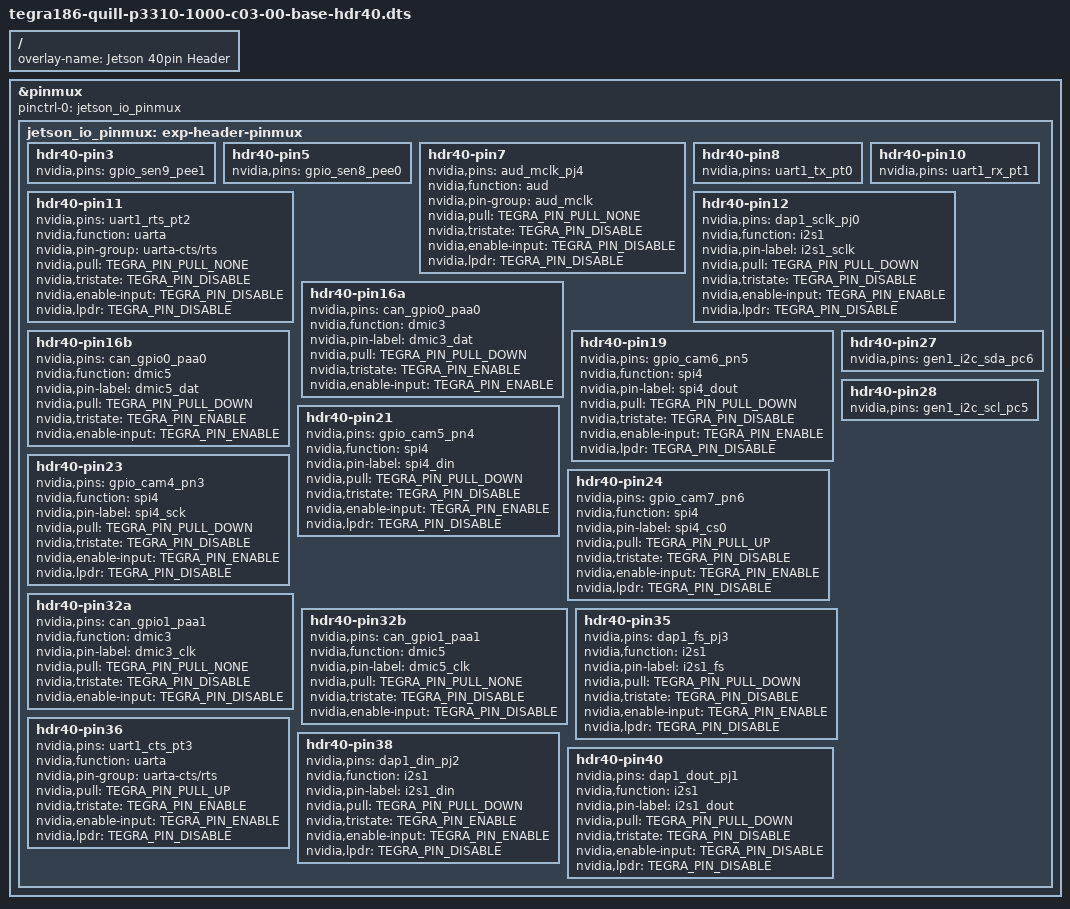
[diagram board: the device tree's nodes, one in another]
// SPDX-License-Identifier: GPL-2.0-only
/*
 * Device-tree overlay for tegra186-quill-p3310-1000-c03-00-base
 * 40-pin Expansion Header.
 *
 * Copyright (c) 2019-2021 NVIDIA CORPORATION. All rights reserved.
 *
 */

/dts-v1/;
/plugin/;

#include <dt-bindings/pinctrl/pinctrl-tegra.h>
#include <dt-common/jetson/tegra186-quill-p3310-1000-c03-00-base.h>

/ {
	overlay-name = "Jetson 40pin Header";
	compatible = JETSON_COMPATIBLE;

	fragment@0 {
		target = <&pinmux>;
		__overlay__ {
			pinctrl-names = "default";
			pinctrl-0 = <&jetson_io_pinmux>;
			jetson_io_pinmux: exp-header-pinmux {
				hdr40-pin3 {
					nvidia,pins = "gpio_sen9_pee1";
				};
				hdr40-pin5 {
					nvidia,pins = "gpio_sen8_pee0";
				};
				hdr40-pin7 {
					nvidia,pins = "aud_mclk_pj4";
					nvidia,function = "aud";
					nvidia,pin-group = "aud_mclk";
					nvidia,pull = <TEGRA_PIN_PULL_NONE>;
					nvidia,tristate = <TEGRA_PIN_DISABLE>;
					nvidia,enable-input = <TEGRA_PIN_DISABLE>;
					nvidia,lpdr = <TEGRA_PIN_DISABLE>;
				};
				hdr40-pin8 {
					nvidia,pins = "uart1_tx_pt0";
				};
				hdr40-pin10 {
					nvidia,pins = "uart1_rx_pt1";
				};
				hdr40-pin11 {
					nvidia,pins = "uart1_rts_pt2";
					nvidia,function = "uarta";
					nvidia,pin-group = "uarta-cts/rts";
					nvidia,pull = <TEGRA_PIN_PULL_NONE>;
					nvidia,tristate = <TEGRA_PIN_DISABLE>;
					nvidia,enable-input = <TEGRA_PIN_DISABLE>;
					nvidia,lpdr = <TEGRA_PIN_DISABLE>;
				};
				hdr40-pin12 {
					nvidia,pins = "dap1_sclk_pj0";
					nvidia,function = "i2s1";
					nvidia,pin-label = "i2s1_sclk";
					nvidia,pull = <TEGRA_PIN_PULL_DOWN>;
					nvidia,tristate = <TEGRA_PIN_DISABLE>;
					nvidia,enable-input = <TEGRA_PIN_ENABLE>;
					nvidia,lpdr = <TEGRA_PIN_DISABLE>;
				};
				hdr40-pin16a {
					nvidia,pins = "can_gpio0_paa0";
					nvidia,function = "dmic3";
					nvidia,pin-label = "dmic3_dat";
					nvidia,pull = <TEGRA_PIN_PULL_DOWN>;
					nvidia,tristate = <TEGRA_PIN_ENABLE>;
					nvidia,enable-input = <TEGRA_PIN_ENABLE>;
				};
				hdr40-pin16b {
					nvidia,pins = "can_gpio0_paa0";
					nvidia,function = "dmic5";
					nvidia,pin-label = "dmic5_dat";
					nvidia,pull = <TEGRA_PIN_PULL_DOWN>;
					nvidia,tristate = <TEGRA_PIN_ENABLE>;
					nvidia,enable-input = <TEGRA_PIN_ENABLE>;
				};
				hdr40-pin19 {
					nvidia,pins = "gpio_cam6_pn5";
					nvidia,function = "spi4";
					nvidia,pin-label = "spi4_dout";
					nvidia,pull = <TEGRA_PIN_PULL_DOWN>;
					nvidia,tristate = <TEGRA_PIN_DISABLE>;
					nvidia,enable-input = <TEGRA_PIN_ENABLE>;
					nvidia,lpdr = <TEGRA_PIN_DISABLE>;
				};
				hdr40-pin21 {
					nvidia,pins = "gpio_cam5_pn4";
					nvidia,function = "spi4";
					nvidia,pin-label = "spi4_din";
					nvidia,pull = <TEGRA_PIN_PULL_DOWN>;
					nvidia,tristate = <TEGRA_PIN_DISABLE>;
					nvidia,enable-input = <TEGRA_PIN_ENABLE>;
					nvidia,lpdr = <TEGRA_PIN_DISABLE>;
				};
				hdr40-pin23 {
					nvidia,pins = "gpio_cam4_pn3";
					nvidia,function = "spi4";
					nvidia,pin-label = "spi4_sck";
					nvidia,pull = <TEGRA_PIN_PULL_DOWN>;
					nvidia,tristate = <TEGRA_PIN_DISABLE>;
					nvidia,enable-input = <TEGRA_PIN_ENABLE>;
					nvidia,lpdr = <TEGRA_PIN_DISABLE>;
				};
				hdr40-pin24 {
					nvidia,pins = "gpio_cam7_pn6";
					nvidia,function = "spi4";
					nvidia,pin-label = "spi4_cs0";
					nvidia,pull = <TEGRA_PIN_PULL_UP>;
					nvidia,tristate = <TEGRA_PIN_DISABLE>;
					nvidia,enable-input = <TEGRA_PIN_ENABLE>;
					nvidia,lpdr = <TEGRA_PIN_DISABLE>;
				};
				hdr40-pin27 {
					nvidia,pins = "gen1_i2c_sda_pc6";
				};
				hdr40-pin28 {
					nvidia,pins = "gen1_i2c_scl_pc5";
				};
				hdr40-pin32a {
					nvidia,pins = "can_gpio1_paa1";
					nvidia,function = "dmic3";
					nvidia,pin-label = "dmic3_clk";
					nvidia,pull = <TEGRA_PIN_PULL_NONE>;
					nvidia,tristate = <TEGRA_PIN_DISABLE>;
					nvidia,enable-input = <TEGRA_PIN_DISABLE>;
				};
				hdr40-pin32b {
					nvidia,pins = "can_gpio1_paa1";
					nvidia,function = "dmic5";
					nvidia,pin-label = "dmic5_clk";
					nvidia,pull = <TEGRA_PIN_PULL_NONE>;
					nvidia,tristate = <TEGRA_PIN_DISABLE>;
					nvidia,enable-input = <TEGRA_PIN_DISABLE>;
				};
				hdr40-pin35 {
					nvidia,pins = "dap1_fs_pj3";
					nvidia,function = "i2s1";
					nvidia,pin-label = "i2s1_fs";
					nvidia,pull = <TEGRA_PIN_PULL_DOWN>;
					nvidia,tristate = <TEGRA_PIN_DISABLE>;
					nvidia,enable-input = <TEGRA_PIN_ENABLE>;
					nvidia,lpdr = <TEGRA_PIN_DISABLE>;
				};
				hdr40-pin36 {
					nvidia,pins = "uart1_cts_pt3";
					nvidia,function = "uarta";
					nvidia,pin-group = "uarta-cts/rts";
					nvidia,pull = <TEGRA_PIN_PULL_UP>;
					nvidia,tristate = <TEGRA_PIN_ENABLE>;
					nvidia,enable-input = <TEGRA_PIN_ENABLE>;
					nvidia,lpdr = <TEGRA_PIN_DISABLE>;
				};
				hdr40-pin38 {
					nvidia,pins = "dap1_din_pj2";
					nvidia,function = "i2s1";
					nvidia,pin-label = "i2s1_din";
					nvidia,pull = <TEGRA_PIN_PULL_DOWN>;
					nvidia,tristate = <TEGRA_PIN_ENABLE>;
					nvidia,enable-input = <TEGRA_PIN_ENABLE>;
					nvidia,lpdr = <TEGRA_PIN_DISABLE>;
				};
				hdr40-pin40 {
					nvidia,pins = "dap1_dout_pj1";
					nvidia,function = "i2s1";
					nvidia,pin-label = "i2s1_dout";
					nvidia,pull = <TEGRA_PIN_PULL_DOWN>;
					nvidia,tristate = <TEGRA_PIN_DISABLE>;
					nvidia,enable-input = <TEGRA_PIN_DISABLE>;
					nvidia,lpdr = <TEGRA_PIN_DISABLE>;
				};
			};
		};
	};
};
